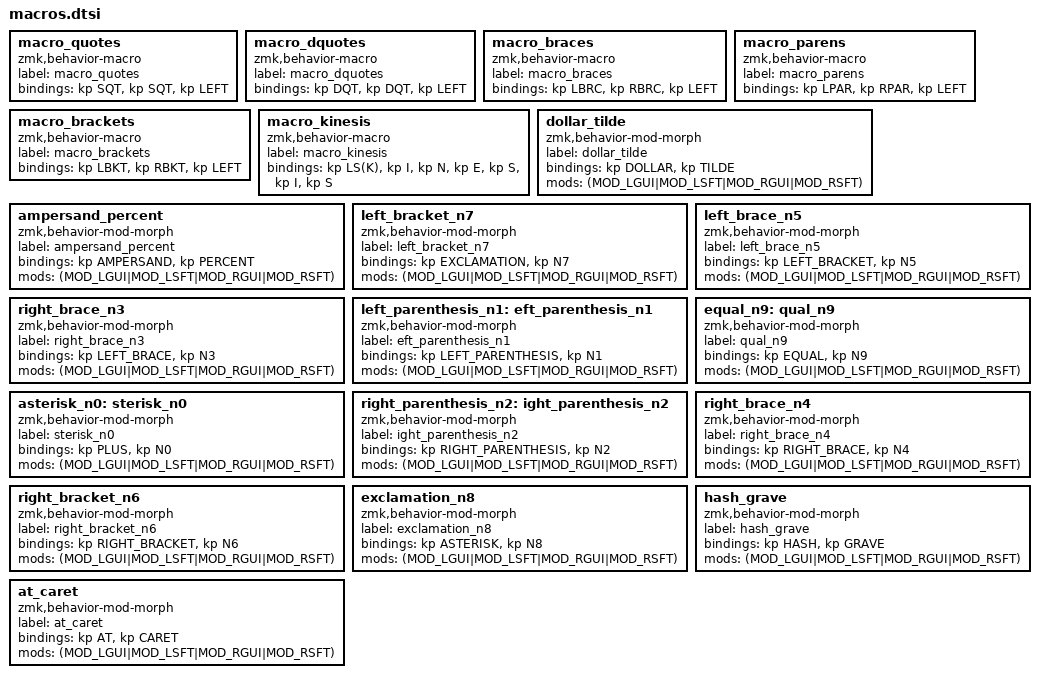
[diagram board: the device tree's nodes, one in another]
  macro_quotes: macro_quotes {
    compatible = "zmk,behavior-macro";
    label = "macro_quotes";
    #binding-cells = <0>;
    bindings = <&kp SQT>, <&kp SQT>, <&kp LEFT>;
  };
  macro_dquotes: macro_dquotes {
    compatible = "zmk,behavior-macro";
    label = "macro_dquotes";
    #binding-cells = <0>;
    bindings = <&kp DQT>, <&kp DQT>, <&kp LEFT>;
  };
  macro_braces: macro_braces {
    compatible = "zmk,behavior-macro";
    label = "macro_braces";
    #binding-cells = <0>;
    bindings = <&kp LBRC>, <&kp RBRC>, <&kp LEFT>;
  };
  macro_parens: macro_parens {
    compatible = "zmk,behavior-macro";
    label = "macro_parens";
    #binding-cells = <0>;
    bindings = <&kp LPAR>, <&kp RPAR>, <&kp LEFT>;
  };
  macro_brackets: macro_brackets {
    compatible = "zmk,behavior-macro";
    label = "macro_brackets";
    #binding-cells = <0>;
    bindings = <&kp LBKT>, <&kp RBKT>, <&kp LEFT>;
  };
  macro_kinesis: macro_kinesis {
    compatible = "zmk,behavior-macro";
    label = "macro_kinesis";
    #binding-cells = <0>;
    bindings = <&kp LS(K)>, <&kp I>, <&kp N>, <&kp E>, <&kp S>, <&kp I>, <&kp S>;
  };
  dollar_tilde: dollar_tilde{
    compatible = "zmk,behavior-mod-morph";
    label = "dollar_tilde";
    #binding-cells = <0>;
    bindings = <&kp DOLLAR>, <&kp TILDE>;
    mods = <(MOD_LGUI|MOD_LSFT|MOD_RGUI|MOD_RSFT)>;
  };   
  ampersand_percent: ampersand_percent{
    compatible = "zmk,behavior-mod-morph";
    label = "ampersand_percent";
    #binding-cells = <0>;
    bindings = <&kp AMPERSAND>, <&kp PERCENT>;
    mods = <(MOD_LGUI|MOD_LSFT|MOD_RGUI|MOD_RSFT)>;
  };   
  left_bracket_n7: left_bracket_n7{
    compatible = "zmk,behavior-mod-morph";
    label = "left_bracket_n7";
    #binding-cells = <0>;
    bindings = <&kp EXCLAMATION>, <&kp N7>;
    mods = <(MOD_LGUI|MOD_LSFT|MOD_RGUI|MOD_RSFT)>;
  };   
  left_brace_n5: left_brace_n5{
    compatible = "zmk,behavior-mod-morph";
    label = "left_brace_n5";
    #binding-cells = <0>;
    bindings = <&kp LEFT_BRACKET>, <&kp N5>;
    mods = <(MOD_LGUI|MOD_LSFT|MOD_RGUI|MOD_RSFT)>;
  };   
  right_brace_n3: right_brace_n3{
    compatible = "zmk,behavior-mod-morph";
    label = "right_brace_n3";
    #binding-cells = <0>;
    bindings = <&kp LEFT_BRACE>, <&kp N3>;
    mods = <(MOD_LGUI|MOD_LSFT|MOD_RGUI|MOD_RSFT)>;
  };   
  left_parenthesis_n1: eft_parenthesis_n1{
    compatible = "zmk,behavior-mod-morph";
    label = "eft_parenthesis_n1";
    #binding-cells = <0>;
    bindings = <&kp LEFT_PARENTHESIS>, <&kp N1>;
    mods = <(MOD_LGUI|MOD_LSFT|MOD_RGUI|MOD_RSFT)>;
  };   
  equal_n9: qual_n9{
    compatible = "zmk,behavior-mod-morph";
    label = "qual_n9";
    #binding-cells = <0>;
    bindings = <&kp EQUAL>, <&kp N9>;
    mods = <(MOD_LGUI|MOD_LSFT|MOD_RGUI|MOD_RSFT)>;
  };   
  asterisk_n0: sterisk_n0{
    compatible = "zmk,behavior-mod-morph";
    label = "sterisk_n0";
    #binding-cells = <0>;
    bindings = <&kp PLUS>, <&kp N0>;
    mods = <(MOD_LGUI|MOD_LSFT|MOD_RGUI|MOD_RSFT)>;
  };   
  right_parenthesis_n2: ight_parenthesis_n2{
    compatible = "zmk,behavior-mod-morph";
    label = "ight_parenthesis_n2";
    #binding-cells = <0>;
    bindings = <&kp RIGHT_PARENTHESIS>, <&kp N2>;
    mods = <(MOD_LGUI|MOD_LSFT|MOD_RGUI|MOD_RSFT)>;
  };   
  right_brace_n4: right_brace_n4{
    compatible = "zmk,behavior-mod-morph";
    label = "right_brace_n4";
    #binding-cells = <0>;
    bindings = <&kp RIGHT_BRACE>, <&kp N4>;
    mods = <(MOD_LGUI|MOD_LSFT|MOD_RGUI|MOD_RSFT)>;
  };   
  right_bracket_n6: right_bracket_n6{
    compatible = "zmk,behavior-mod-morph";
    label = "right_bracket_n6";
    #binding-cells = <0>;
    bindings = <&kp RIGHT_BRACKET>, <&kp N6>;
    mods = <(MOD_LGUI|MOD_LSFT|MOD_RGUI|MOD_RSFT)>;
  };   
  exclamation_n8: exclamation_n8{
    compatible = "zmk,behavior-mod-morph";
    label = "exclamation_n8";
    #binding-cells = <0>;
    bindings = <&kp ASTERISK>, <&kp N8>;
    mods = <(MOD_LGUI|MOD_LSFT|MOD_RGUI|MOD_RSFT)>;
  };   
  hash_grave: hash_grave{
    compatible = "zmk,behavior-mod-morph";
    label = "hash_grave";
    #binding-cells = <0>;
    bindings = <&kp HASH>, <&kp GRAVE>;
    mods = <(MOD_LGUI|MOD_LSFT|MOD_RGUI|MOD_RSFT)>;
  };   
  at_caret: at_caret{
    compatible = "zmk,behavior-mod-morph";
    label = "at_caret";
    #binding-cells = <0>;
    bindings = <&kp AT>, <&kp CARET>;
    mods = <(MOD_LGUI|MOD_LSFT|MOD_RGUI|MOD_RSFT)>;
  };   
